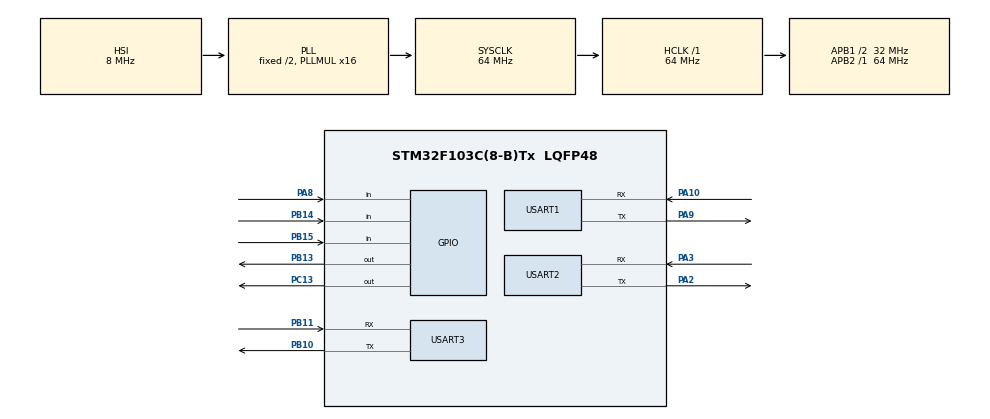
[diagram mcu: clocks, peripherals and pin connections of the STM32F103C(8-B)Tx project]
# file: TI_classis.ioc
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Dma.Request0=USART1_RX
Dma.Request1=USART2_RX
Dma.Request2=USART3_RX
Dma.USART1_RX.0.Direction=DMA_PERIPH_TO_MEMORY
Dma.USART1_RX.0.Instance=DMA1_Channel5
Dma.USART1_RX.0.MemDataAlignment=DMA_MDATAALIGN_BYTE
Dma.USART1_RX.0.MemInc=DMA_MINC_ENABLE
Dma.USART1_RX.0.Mode=DMA_CIRCULAR
Dma.USART1_RX.0.PeriphDataAlignment=DMA_PDATAALIGN_BYTE
Dma.USART1_RX.0.PeriphInc=DMA_PINC_DISABLE
Dma.USART1_RX.0.Priority=DMA_PRIORITY_LOW
Dma.USART2_RX.1.Direction=DMA_PERIPH_TO_MEMORY
Dma.USART2_RX.1.Instance=DMA1_Channel6
Dma.USART2_RX.1.MemDataAlignment=DMA_MDATAALIGN_BYTE
Dma.USART2_RX.1.MemInc=DMA_MINC_ENABLE
Dma.USART2_RX.1.Mode=DMA_CIRCULAR
Dma.USART2_RX.1.PeriphDataAlignment=DMA_PDATAALIGN_BYTE
Dma.USART2_RX.1.PeriphInc=DMA_PINC_DISABLE
Dma.USART2_RX.1.Priority=DMA_PRIORITY_LOW
Dma.USART3_RX.2.Direction=DMA_PERIPH_TO_MEMORY
Dma.USART3_RX.2.Instance=DMA1_Channel3
Dma.USART3_RX.2.MemDataAlignment=DMA_MDATAALIGN_BYTE
Dma.USART3_RX.2.MemInc=DMA_MINC_ENABLE
Dma.USART3_RX.2.Mode=DMA_CIRCULAR
Dma.USART3_RX.2.PeriphDataAlignment=DMA_PDATAALIGN_BYTE
Dma.USART3_RX.2.PeriphInc=DMA_PINC_DISABLE
Dma.USART3_RX.2.Priority=DMA_PRIORITY_LOW
Mcu.Family=STM32F1
Mcu.Name=STM32F103C(8-B)Tx
Mcu.Package=LQFP48
NVIC.DMA1_Channel3_IRQn=true\:0\:0\:false\:false\:true\:false\:true\:true
NVIC.DMA1_Channel5_IRQn=true\:0\:0\:false\:false\:true\:false\:true\:true
NVIC.DMA1_Channel6_IRQn=true\:0\:0\:false\:false\:true\:false\:true\:true
NVIC.PriorityGroup=NVIC_PRIORITYGROUP_4
NVIC.TIM1_UP_IRQn=true\:0\:0\:false\:false\:true\:true\:true\:true
NVIC.USART1_IRQn=true\:0\:0\:false\:false\:true\:true\:true\:true
NVIC.USART2_IRQn=true\:0\:0\:false\:false\:true\:true\:true\:true
NVIC.USART3_IRQn=true\:0\:0\:false\:false\:true\:true\:true\:true
PA10.Mode=Asynchronous
PA10.Signal=USART1_RX
PA13.Mode=Serial_Wire
PA13.Signal=SYS_JTMS-SWDIO
PA14.Mode=Serial_Wire
PA14.Signal=SYS_JTCK-SWCLK
PA2.Mode=Asynchronous
PA2.Signal=USART2_TX
PA3.Mode=Asynchronous
PA3.Signal=USART2_RX
PA8.Signal=GPIO_Input
PA9.Mode=Asynchronous
PA9.Signal=USART1_TX
PB10.Mode=Asynchronous
PB10.Signal=USART3_TX
PB11.Mode=Asynchronous
PB11.Signal=USART3_RX
PB13.GPIO_ModeDefaultOutputPP=GPIO_MODE_OUTPUT_OD
PB13.GPIO_PuPd=GPIO_PULLUP
PB13.Signal=GPIO_Output
PB14.GPIO_PuPd=GPIO_NOPULL
PB14.Signal=GPIO_Input
PB15.GPIO_PuPd=GPIO_PULLUP
PB15.Signal=GPIO_Input
PC13-TAMPER-RTC.Signal=GPIO_Output
ProjectManager.HeapSize=0x200
ProjectManager.StackSize=0x400
ProjectManager.TargetToolchain=STM32CubeIDE
RCC.AHBFreq_Value=64000000
RCC.APB1CLKDivider=RCC_HCLK_DIV2
RCC.APB1Freq_Value=32000000
RCC.APB1TimFreq_Value=64000000
RCC.APB2Freq_Value=64000000
RCC.APB2TimFreq_Value=64000000
RCC.HCLKFreq_Value=64000000
RCC.PLLMUL=RCC_PLL_MUL16
RCC.SYSCLKFreq_VALUE=64000000
RCC.SYSCLKSource=RCC_SYSCLKSOURCE_PLLCLK
RCC.USBFreq_Value=64000000
TIM1.Period=9999
TIM1.Prescaler=63
USART1.VirtualMode=VM_ASYNC
USART2.VirtualMode=VM_ASYNC
USART3.VirtualMode=VM_ASYNC
VP_TIM1_VS_ClockSourceINT.Mode=Internal
board=custom

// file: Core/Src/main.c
/* USER CODE BEGIN Header */
/**
  ******************************************************************************
  * @file           : main.c
  * @brief          : Main program body
  ******************************************************************************
  * @attention
  *
  * Copyright (c) 2026 STMicroelectronics.
  * All rights reserved.
  *
  * This software is licensed under terms that can be found in the LICENSE file
  * in the root directory of this software component.
  * If no LICENSE file comes with this software, it is provided AS-IS.
  *
  ******************************************************************************
  */
/* USER CODE END Header */
#include "main.h"
#include "dma.h"
#include "tim.h"
#include "usart.h"
#include "gpio.h"

/* USER CODE BEGIN Includes */
#include "uart.h"
#include <stdio.h>
#include <stdarg.h>
#include "JC.h"
#include "vision.h"
#include "Gimbal_track.h"
/* USER CODE END Includes */

void SystemClock_Config(void);

/* USER CODE BEGIN 0 */
void HAL_TIM_PeriodElapsedCallback(TIM_HandleTypeDef *htim)
{
    if (htim->Instance == TIM1)
    {
        Gimbal_Track_Task(); // 调用云台跟踪任务
    }
}
/* USER CODE END 0 */

int main(void)
{

  /* MCU Configuration--------------------------------------------------------*/

  /* Reset of all peripherals, Initializes the Flash interface and the Systick. */
  HAL_Init();

  /* Configure the system clock */
  SystemClock_Config();

  /* Initialize all configured peripherals */
  MX_GPIO_Init();
  MX_DMA_Init();
  MX_USART1_UART_Init();
  MX_USART2_UART_Init();
  MX_USART3_UART_Init();
  MX_TIM1_Init();
  /* USER CODE BEGIN 2 */
  // JC_Motor_SetZero();
  // Vision_Receiver_Init();
  Gimbal_PID_Init();

  /* USER CODE END 2 */

  /* Infinite loop */
  while (1)
  {

  }
}

void SystemClock_Config(void)
{
  RCC_OscInitTypeDef RCC_OscInitStruct = {0};
  RCC_ClkInitTypeDef RCC_ClkInitStruct = {0};

  /** Initializes the RCC Oscillators according to the specified parameters
  * in the RCC_OscInitTypeDef structure.
  */
  RCC_OscInitStruct.OscillatorType = RCC_OSCILLATORTYPE_HSI;
  RCC_OscInitStruct.HSIState = RCC_HSI_ON;
  RCC_OscInitStruct.HSICalibrationValue = RCC_HSICALIBRATION_DEFAULT;
  RCC_OscInitStruct.PLL.PLLState = RCC_PLL_ON;
  RCC_OscInitStruct.PLL.PLLSource = RCC_PLLSOURCE_HSI_DIV2;
  RCC_OscInitStruct.PLL.PLLMUL = RCC_PLL_MUL16;
  if (HAL_RCC_OscConfig(&RCC_OscInitStruct) != HAL_OK)
  {
    Error_Handler();
  }

  /** Initializes the CPU, AHB and APB buses clocks
  */
  RCC_ClkInitStruct.ClockType = RCC_CLOCKTYPE_HCLK|RCC_CLOCKTYPE_SYSCLK
                              |RCC_CLOCKTYPE_PCLK1|RCC_CLOCKTYPE_PCLK2;
  RCC_ClkInitStruct.SYSCLKSource = RCC_SYSCLKSOURCE_PLLCLK;
  RCC_ClkInitStruct.AHBCLKDivider = RCC_SYSCLK_DIV1;
  RCC_ClkInitStruct.APB1CLKDivider = RCC_HCLK_DIV2;
  RCC_ClkInitStruct.APB2CLKDivider = RCC_HCLK_DIV1;

  if (HAL_RCC_ClockConfig(&RCC_ClkInitStruct, FLASH_LATENCY_2) != HAL_OK)
  {
    Error_Handler();
  }
}

void Error_Handler(void)
{
  __disable_irq();
  while (1)
  {
  }
}
